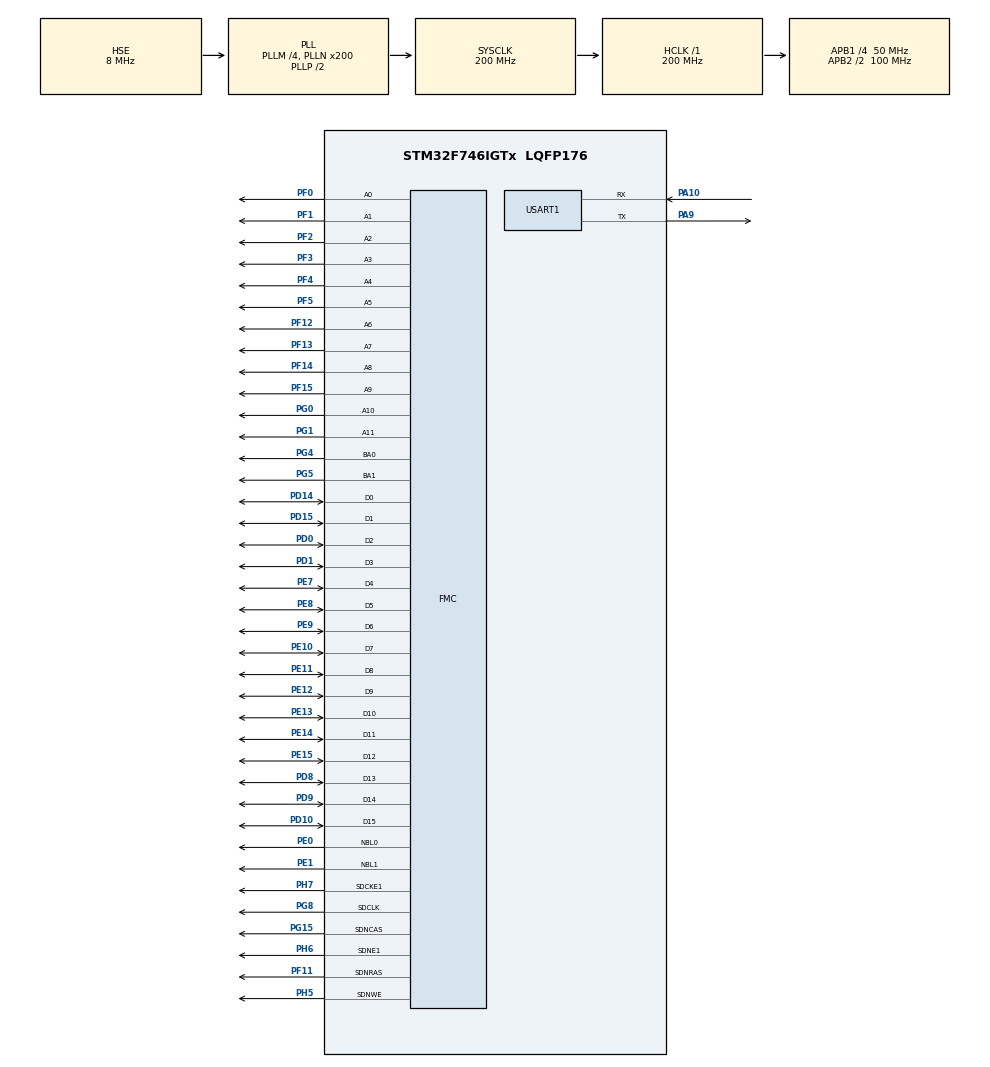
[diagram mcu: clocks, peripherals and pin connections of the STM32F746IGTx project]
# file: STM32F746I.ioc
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Mcu.Family=STM32F7
SH.FMC_D7_DA7.0=FMC_D7,sd-16b-d1
SH.FMC_A8.0=FMC_A8,12b-sda1
RCC.CortexFreq_Value=200000000
FMC.RCDDelay1=2
FMC.SDClockPeriod1=FMC_SDRAM_CLOCK_PERIOD_2
SH.FMC_A0.0=FMC_A0,12b-sda1
SH.FMC_D14_DA14.0=FMC_D14,sd-16b-d1
PG4.Signal=FMC_A14_BA0
PG8.Signal=FMC_SDCLK
USART1.WordLength=WORDLENGTH_8B
PG0.Signal=FMC_A10
SH.FMC_NBL0.0=FMC_NBL0,Sd2ByteEnable1
FMC.LoadToActiveDelay1=2
CORTEX_M7.PREFETCH_ENABLE=1
SH.FMC_D6_DA6.0=FMC_D6,sd-16b-d1
SH.FMC_A14_BA0.0=FMC_BA0,FourSdramBanks1
SH.FMC_A11.0=FMC_A11,12b-sda1
SH.FMC_D5_DA5.0=FMC_D5,sd-16b-d1
PG15.Signal=FMC_SDNCAS
RCC.SYSCLKSource=RCC_SYSCLKSOURCE_PLLCLK
ProjectManager.StackSize=0x400
SH.FMC_A15_BA1.0=FMC_BA1,FourSdramBanks1
SH.FMC_D9_DA9.0=FMC_D9,sd-16b-d1
SH.FMC_A7.0=FMC_A7,12b-sda1
PH5.Signal=FMC_SDNWE
SH.FMC_SDNWE.0=FMC_SDNWE,12b-sda1
PH0/OSC_IN.Mode=HSE-External-Oscillator
SH.FMC_D11_DA11.0=FMC_D11,sd-16b-d1
RCC.HCLKFreq_Value=200000000
RCC.APB2TimFreq_Value=200000000
SH.FMC_NBL1.0=FMC_NBL1,Sd2ByteEnable1
PH1/OSC_OUT.Signal=RCC_OSC_OUT
PF12.Signal=FMC_A6
PD0.Signal=FMC_D2_DA2
PD8.Signal=FMC_D13_DA13
PE1.Signal=FMC_NBL1
SH.FMC_A10.0=FMC_A10,12b-sda1
RCC.AHBFreq_Value=200000000
RCC.HSE_VALUE=8000000
PB3.Mode=JTAG_5_pins
SH.FMC_D8_DA8.0=FMC_D8,sd-16b-d1
FMC.ExitSelfRefreshDelay1=7
FMC.RPDelay1=2
PA15.Mode=JTAG_5_pins
FMC.SelfRefreshTime1=4
SH.FMC_D2_DA2.0=FMC_D2,sd-16b-d1
PB4.Mode=JTAG_5_pins
PE13.Signal=FMC_D10_DA10
PE9.Signal=FMC_D6_DA6
PA14.Mode=JTAG_5_pins
SH.FMC_A2.0=FMC_A2,12b-sda1
Dma.MEMTOMEM.0.Instance=DMA2_Stream0
PF11.Signal=FMC_SDNRAS
SH.FMC_D1_DA1.0=FMC_D1,sd-16b-d1
FMC.ReadPipeDelay1=FMC_SDRAM_RPIPE_DELAY_1
FMC.ReadPipeDelay2=FMC_SDRAM_RPIPE_DELAY_1
PF3.Signal=FMC_A3
SH.FMC_SDNRAS.0=FMC_SDNRAS,12b-sda1
PH1/OSC_OUT.Mode=HSE-External-Oscillator
PE10.Signal=FMC_D7_DA7
PH7.Mode=SdramChipSelect2_1
Mcu.Package=LQFP176
SH.FMC_D0_DA0.0=FMC_D0,sd-16b-d1
Dma.MEMTOMEM.0.PeriphInc=DMA_PINC_ENABLE
PA10.Signal=USART1_RX
SH.FMC_A9.0=FMC_A9,12b-sda1
PA15.Signal=SYS_JTDI
Dma.MEMTOMEM.0.FIFOThreshold=DMA_FIFO_THRESHOLD_FULL
SH.FMC_D4_DA4.0=FMC_D4,sd-16b-d1
FMC.WriteRecoveryTime1=2
PF5.Signal=FMC_A5
SH.FMC_A1.0=FMC_A1,12b-sda1
PH7.Signal=FMC_SDCKE1
RCC.APB2CLKDivider=RCC_HCLK_DIV2
SH.FMC_SDCLK.0=FMC_SDCLK,12b-sda1
PF14.Signal=FMC_A8
RCC.APB1TimFreq_Value=100000000
FMC.RowBitsNumber1=FMC_SDRAM_ROW_BITS_NUM_12
FMC.RowCycleDelay2=6
PF0.Signal=FMC_A0
FMC.RowCycleDelay1=6
PE7.Signal=FMC_D4_DA4
Dma.Request0=MEMTOMEM
PD15.Signal=FMC_D1_DA1
SH.FMC_D3_DA3.0=FMC_D3,sd-16b-d1
PB4.Signal=SYS_JTRST
RCC.PLLSourceVirtual=RCC_PLLSOURCE_HSE
SH.FMC_A4.0=FMC_A4,12b-sda1
Dma.MEMTOMEM.0.MemDataAlignment=DMA_MDATAALIGN_WORD
CORTEX_M7.CPU_ICache=Enabled
PA10.Mode=Asynchronous
Dma.MEMTOMEM.0.Priority=DMA_PRIORITY_HIGH
PG1.Signal=FMC_A11
PG5.Signal=FMC_A15_BA1
SH.FMC_D10_DA10.0=FMC_D10,sd-16b-d1
PD1.Signal=FMC_D3_DA3
PD9.Signal=FMC_D14_DA14
RCC.APB1CLKDivider=RCC_HCLK_DIV4
PD10.Signal=FMC_D15_DA15
USART1.VirtualMode-Asynchronous=VM_ASYNC
PA13.Signal=SYS_JTMS-SWDIO
SH.FMC_A3.0=FMC_A3,12b-sda1
PA9.Mode=Asynchronous
FMC.CASLatency1=FMC_SDRAM_CAS_LATENCY_3
ProjectManager.TargetToolchain=STM32CubeIDE
SH.FMC_D15_DA15.0=FMC_D15,sd-16b-d1
SH.FMC_D13_DA13.0=FMC_D13,sd-16b-d1
PA9.Signal=USART1_TX
PF2.Signal=FMC_A2
RCC.USBFreq_Value=200000000
Dma.MEMTOMEM.0.FIFOMode=DMA_FIFOMODE_ENABLE
PE11.Signal=FMC_D8_DA8
CORTEX_M7.FlashInterface=TCM_Enabled
RCC.LSE_VALUE=32768
Dma.MEMTOMEM.0.MemBurst=DMA_MBURST_SINGLE
board=STM32F746I
RCC.VCOOutputFreq_Value=400000000
PH6.Mode=SdramChipSelect2_1
FMC.ReadBurst1=FMC_SDRAM_RBURST_DISABLE
PH0/OSC_IN.Signal=RCC_OSC_IN
SH.FMC_A6.0=FMC_A6,12b-sda1
RCC.APB2Freq_Value=100000000
PE14.Signal=FMC_D11_DA11
PE15.Signal=FMC_D12_DA12
PE8.Signal=FMC_D5_DA5
SH.FMC_D12_DA12.0=FMC_D12,sd-16b-d1
PF15.Signal=FMC_A9
PF13.Signal=FMC_A7
PF1.Signal=FMC_A1
PA13.Mode=JTAG_5_pins
SH.FMC_SDNCAS.0=FMC_SDNCAS,12b-sda1
Mcu.Name=STM32F746IGTx
PE0.Signal=FMC_NBL0
PE12.Signal=FMC_D9_DA9
PD14.Signal=FMC_D0_DA0
Dma.MEMTOMEM.0.PeriphDataAlignment=DMA_PDATAALIGN_WORD
PB3.Signal=SYS_JTDO-SWO
RCC.SYSCLKFreq_VALUE=200000000
Dma.MEMTOMEM.0.Mode=DMA_NORMAL
Dma.MEMTOMEM.0.PeriphBurst=DMA_PBURST_SINGLE
Dma.MEMTOMEM.0.MemInc=DMA_MINC_ENABLE
SH.FMC_A5.0=FMC_A5,12b-sda1
PA14.Signal=SYS_JTCK-SWCLK
ProjectManager.HeapSize=0x200
PH6.Signal=FMC_SDNE1
RCC.HSI_VALUE=16000000
NVIC.PriorityGroup=NVIC_PRIORITYGROUP_4
RCC.PLLM=4
RCC.PLLN=200
Dma.MEMTOMEM.0.Direction=DMA_MEMORY_TO_MEMORY
PF4.Signal=FMC_A4
CORTEX_M7.CPU_DCache=Enabled
RCC.APB1Freq_Value=50000000

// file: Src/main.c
/* USER CODE BEGIN Header */
/**
  ******************************************************************************
  * @file           : main.c
  * @brief          : Main program body
  ******************************************************************************
  * @attention
  *
  * <h2><center>&copy; Copyright (c) 2020 STMicroelectronics.
  * All rights reserved.</center></h2>
  *
  * This software component is licensed by ST under BSD 3-Clause license,
  * the "License"; You may not use this file except in compliance with the
  * License. You may obtain a copy of the License at:
  *                        opensource.org/licenses/BSD-3-Clause
  *
  ******************************************************************************
  */
/* USER CODE END Header */
#include "main.h"
#include "dma.h"
#include "usart.h"
#include "gpio.h"
#include "fmc.h"

/* USER CODE BEGIN Includes */

#include "stm32f746g_sdram.h"

/* USER CODE END Includes */

void SystemClock_Config(void);

/* USER CODE BEGIN 0 */

extern SDRAM_HandleTypeDef hsdram1;

/* USER CODE END 0 */

int main(void)
{

  /* Enable I-Cache---------------------------------------------------------*/
  SCB_EnableICache();

  /* Enable D-Cache---------------------------------------------------------*/
  SCB_EnableDCache();

  /* MCU Configuration--------------------------------------------------------*/

  /* Reset of all peripherals, Initializes the Flash interface and the Systick. */
  HAL_Init();

  /* Configure the system clock */
  SystemClock_Config();

  /* Initialize all configured peripherals */
  MX_GPIO_Init();
  MX_DMA_Init();
  MX_FMC_Init();
  MX_USART1_UART_Init();
  /* USER CODE BEGIN 2 */

  BSP_SDRAM_Init();

  /* USER CODE END 2 */

  /* Infinite loop */
  while (1)
  {

	  const  __IO uint8_t * SDRAM_base = ( __IO uint8_t *) 0xD0000000;
	  const uint32_t SDRAM_size = 8 * 1048576; 	// SDRAM 64 MBit = 8 MByte

	  __IO uint8_t * SDRAM_now = ( __IO uint8_t *) SDRAM_base;

	  for(uint32_t i = 0; i < SDRAM_size; i++) {
		  *(__IO uint8_t *)(SDRAM_now++) = i & 0xFF;
	  }

	  // dummy, just to be able to put breakpoint here
	  SDRAM_now = (uint8_t *) SDRAM_base;

  }
}

void SystemClock_Config(void)
{
  RCC_OscInitTypeDef RCC_OscInitStruct = {0};
  RCC_ClkInitTypeDef RCC_ClkInitStruct = {0};
  RCC_PeriphCLKInitTypeDef PeriphClkInitStruct = {0};

  /** Configure the main internal regulator output voltage
  */
  __HAL_RCC_PWR_CLK_ENABLE();
  __HAL_PWR_VOLTAGESCALING_CONFIG(PWR_REGULATOR_VOLTAGE_SCALE1);
  /** Initializes the RCC Oscillators according to the specified parameters
  * in the RCC_OscInitTypeDef structure.
  */
  RCC_OscInitStruct.OscillatorType = RCC_OSCILLATORTYPE_HSE;
  RCC_OscInitStruct.HSEState = RCC_HSE_ON;
  RCC_OscInitStruct.PLL.PLLState = RCC_PLL_ON;
  RCC_OscInitStruct.PLL.PLLSource = RCC_PLLSOURCE_HSE;
  RCC_OscInitStruct.PLL.PLLM = 4;
  RCC_OscInitStruct.PLL.PLLN = 200;
  RCC_OscInitStruct.PLL.PLLP = RCC_PLLP_DIV2;
  RCC_OscInitStruct.PLL.PLLQ = 2;
  if (HAL_RCC_OscConfig(&RCC_OscInitStruct) != HAL_OK)
  {
    Error_Handler();
  }
  /** Activate the Over-Drive mode
  */
  if (HAL_PWREx_EnableOverDrive() != HAL_OK)
  {
    Error_Handler();
  }
  /** Initializes the CPU, AHB and APB buses clocks
  */
  RCC_ClkInitStruct.ClockType = RCC_CLOCKTYPE_HCLK|RCC_CLOCKTYPE_SYSCLK
                              |RCC_CLOCKTYPE_PCLK1|RCC_CLOCKTYPE_PCLK2;
  RCC_ClkInitStruct.SYSCLKSource = RCC_SYSCLKSOURCE_PLLCLK;
  RCC_ClkInitStruct.AHBCLKDivider = RCC_SYSCLK_DIV1;
  RCC_ClkInitStruct.APB1CLKDivider = RCC_HCLK_DIV4;
  RCC_ClkInitStruct.APB2CLKDivider = RCC_HCLK_DIV2;

  if (HAL_RCC_ClockConfig(&RCC_ClkInitStruct, FLASH_LATENCY_6) != HAL_OK)
  {
    Error_Handler();
  }
  PeriphClkInitStruct.PeriphClockSelection = RCC_PERIPHCLK_USART1;
  PeriphClkInitStruct.Usart1ClockSelection = RCC_USART1CLKSOURCE_PCLK2;
  if (HAL_RCCEx_PeriphCLKConfig(&PeriphClkInitStruct) != HAL_OK)
  {
    Error_Handler();
  }
}

void Error_Handler(void)
{
}

/************************ (C) COPYRIGHT STMicroelectronics *****END OF FILE****/
